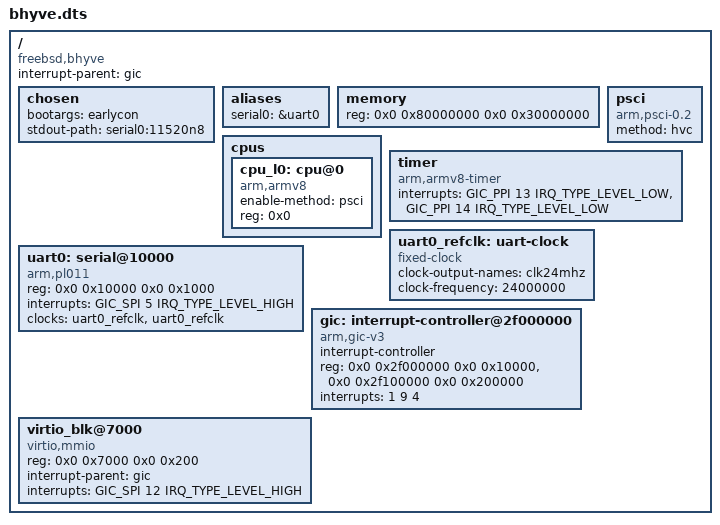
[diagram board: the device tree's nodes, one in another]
/dts-v1/;

#include <dt-bindings/interrupt-controller/arm-gic.h>
#include <dt-bindings/interrupt-controller/irq.h>

/ {
	compatible = "freebsd,bhyve";

	interrupt-parent = <&gic>;
	#address-cells = <2>;
	#size-cells = <2>;

	chosen {
		bootargs = "earlycon";
		stdout-path = "serial0:11520n8";
	};

	aliases {
		serial0 = &uart0;
};

	/* 768MB */
	memory {
		reg = <0x0 0x80000000 0x0 0x30000000>;
	};

	cpus {
		#address-cells = <1>;
		#size-cells = <0>;

		cpu_l0: cpu@0 {
			device_type = "cpu";
			compatible = "arm,armv8";
			enable-method = "psci";
			reg = <0x0>;
		};
		/*
		cpu_l1: cpu@1 {
			device_type = "cpu";
			compatible = "arm,armv8";
			enable-method = "psci";
			reg = <0x1>;
		};
		*/
	};

	psci {
		compatible = "arm,psci-0.2";
		method = "hvc";
	};

	timer {
		compatible = "arm,armv8-timer";
		interrupts = <GIC_PPI 13 IRQ_TYPE_LEVEL_LOW>,
			     <GIC_PPI 14 IRQ_TYPE_LEVEL_LOW>;
	};

	uart0_refclk: uart-clock {
		compatible = "fixed-clock";
		clock-output-names = "clk24mhz";
		#clock-cells = <0>;
		clock-frequency = <24000000>;
	};
	uart0: serial@10000 {
		compatible = "arm,pl011", "arm,primecell";
		reg = <0x0 0x10000 0x0 0x1000>;
		interrupts = <GIC_SPI 5 IRQ_TYPE_LEVEL_HIGH>;
		clocks = <&uart0_refclk>, <&uart0_refclk>;
		clock-names = "uartclk", "apb_pclk";
	};
	gic: interrupt-controller@2f000000 {
		compatible = "arm,gic-v3";
		#interrupt-cells = <3>;
		#address-cells = <2>;
		interrupt-controller;
		reg = <0x0 0x2f000000 0x0 0x10000>,	/* GICD */
		      <0x0 0x2f100000 0x0 0x200000>;	/* GICR */
		interrupts = <1 9 4>;
	};


	virtio_blk@7000 {
		compatible = "virtio,mmio";
		reg = <0x0 0x7000 0x0 0x200>;
		interrupt-parent=<&gic>;
		interrupts = <GIC_SPI 12 IRQ_TYPE_LEVEL_HIGH>;
	};
};
